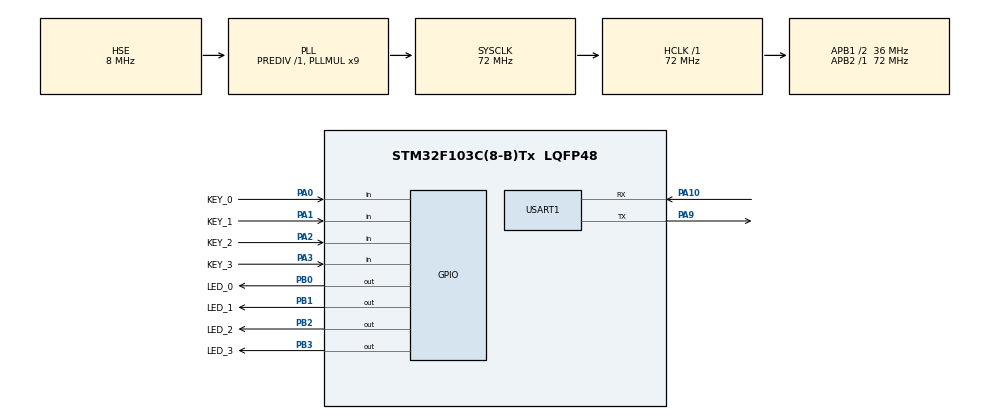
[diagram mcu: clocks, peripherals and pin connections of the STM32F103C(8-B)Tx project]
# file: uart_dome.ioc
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Mcu.Family=STM32F1
Mcu.Name=STM32F103C(8-B)Tx
Mcu.Package=LQFP48
NVIC.PriorityGroup=NVIC_PRIORITYGROUP_4
NVIC.TIM2_IRQn=true\:0\:0\:false\:false\:true\:true\:true
NVIC.USART1_IRQn=true\:0\:0\:false\:false\:true\:true\:true
PA0-WKUP.GPIO_Label=KEY_0
PA0-WKUP.GPIO_PuPd=GPIO_PULLUP
PA0-WKUP.Signal=GPIO_Input
PA1.GPIO_Label=KEY_1
PA1.GPIO_PuPd=GPIO_PULLUP
PA1.Signal=GPIO_Input
PA10.Mode=Asynchronous
PA10.Signal=USART1_RX
PA13.Mode=Serial_Wire
PA13.Signal=SYS_JTMS-SWDIO
PA14.Mode=Serial_Wire
PA14.Signal=SYS_JTCK-SWCLK
PA2.GPIO_Label=KEY_2
PA2.GPIO_PuPd=GPIO_PULLUP
PA2.Signal=GPIO_Input
PA3.GPIO_Label=KEY_3
PA3.GPIO_PuPd=GPIO_PULLUP
PA3.Signal=GPIO_Input
PA9.Mode=Asynchronous
PA9.Signal=USART1_TX
PB0.GPIO_Label=LED_0
PB0.GPIO_PuPd=GPIO_PULLUP
PB0.Signal=GPIO_Output
PB1.GPIO_Label=LED_1
PB1.GPIO_PuPd=GPIO_PULLUP
PB1.Signal=GPIO_Output
PB2.GPIO_Label=LED_2
PB2.GPIO_PuPd=GPIO_PULLUP
PB2.Signal=GPIO_Output
PB3.GPIO_Label=LED_3
PB3.GPIO_PuPd=GPIO_PULLUP
PB3.Signal=GPIO_Output
PC14-OSC32_IN.Mode=LSE-External-Oscillator
PC14-OSC32_IN.Signal=RCC_OSC32_IN
PC15-OSC32_OUT.Mode=LSE-External-Oscillator
PC15-OSC32_OUT.Signal=RCC_OSC32_OUT
PD0-OSC_IN.Mode=HSE-External-Oscillator
PD0-OSC_IN.Signal=RCC_OSC_IN
PD1-OSC_OUT.Mode=HSE-External-Oscillator
PD1-OSC_OUT.Signal=RCC_OSC_OUT
ProjectManager.HeapSize=0x200
ProjectManager.StackSize=0x400
ProjectManager.TargetToolchain=STM32CubeIDE
RCC.AHBFreq_Value=72000000
RCC.APB1CLKDivider=RCC_HCLK_DIV2
RCC.APB1Freq_Value=36000000
RCC.APB1TimFreq_Value=72000000
RCC.APB2Freq_Value=72000000
RCC.APB2TimFreq_Value=72000000
RCC.HCLKFreq_Value=72000000
RCC.PLLMUL=RCC_PLL_MUL9
RCC.PLLSourceVirtual=RCC_PLLSOURCE_HSE
RCC.SYSCLKFreq_VALUE=72000000
RCC.SYSCLKSource=RCC_SYSCLKSOURCE_PLLCLK
RCC.USBFreq_Value=72000000
TIM2.AutoReloadPreload=TIM_AUTORELOAD_PRELOAD_DISABLE
TIM2.Period=5
TIM2.Prescaler=36000-1
USART1.VirtualMode=VM_ASYNC
VP_TIM2_VS_ClockSourceINT.Mode=Internal
board=custom

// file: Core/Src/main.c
/* USER CODE BEGIN Header */
/**
  ******************************************************************************
  * @file           : main.c
  * @brief          : Main program body
  ******************************************************************************
  * @attention
  *
  * <h2><center>&copy; Copyright (c) 2020 STMicroelectronics.
  * All rights reserved.</center></h2>
  *
  * This software component is licensed by ST under BSD 3-Clause license,
  * the "License"; You may not use this file except in compliance with the
  * License. You may obtain a copy of the License at:
  *                        opensource.org/licenses/BSD-3-Clause
  *
  ******************************************************************************
  */
/* USER CODE END Header */

#include "main.h"

/* USER CODE BEGIN Includes */

uint8_t buffer[2];  //串口接收buffer
float a=5.5;

/* USER CODE END Includes */

TIM_HandleTypeDef htim2;

UART_HandleTypeDef huart1;

void SystemClock_Config(void);
static void MX_GPIO_Init(void);
static void MX_TIM2_Init(void);
static void MX_USART1_UART_Init(void);

int main(void)
{
  /* USER CODE BEGIN 1 */

	//uart_frame_id

  /* USER CODE END 1 */

  /* MCU Configuration--------------------------------------------------------*/

  /* Reset of all peripherals, Initializes the Flash interface and the Systick. */
  HAL_Init();

  /* Configure the system clock */
  SystemClock_Config();

  /* Initialize all configured peripherals */
  MX_GPIO_Init();
  MX_TIM2_Init();
  MX_USART1_UART_Init();
  /* USER CODE BEGIN 2 */

  HAL_TIM_Base_Start_IT(&htim2);  //Start timer interrupt启动定时器中�
  HAL_UART_Receive_IT(&huart1,(uint8_t*)&buffer,1);  //Start uart interrupt

  HAL_UART_Transmit(&huart1,(uint8_t*)"uart_test_ok",16,10);
  /* USER CODE END 2 */

  /* Infinite loop */
  /* USER CODE BEGIN WHILE */
  while (1)
  {

//	  sprintf((uint8_t*)buffer, (uint8_t*)"An approximation ofPi is %f",(uint8_t)a);
//	  HAL_UART_Transmit(&huart1,buffer,sizeof(buffer),10);
//      HAL_Delay(100);

	 Key_Processing();

    /* USER CODE END WHILE */

  }
}

void SystemClock_Config(void)
{
  RCC_OscInitTypeDef RCC_OscInitStruct = {0};
  RCC_ClkInitTypeDef RCC_ClkInitStruct = {0};

  /** Initializes the CPU, AHB and APB busses clocks
  */
  RCC_OscInitStruct.OscillatorType = RCC_OSCILLATORTYPE_HSE;
  RCC_OscInitStruct.HSEState = RCC_HSE_ON;
  RCC_OscInitStruct.HSEPredivValue = RCC_HSE_PREDIV_DIV1;
  RCC_OscInitStruct.HSIState = RCC_HSI_ON;
  RCC_OscInitStruct.PLL.PLLState = RCC_PLL_ON;
  RCC_OscInitStruct.PLL.PLLSource = RCC_PLLSOURCE_HSE;
  RCC_OscInitStruct.PLL.PLLMUL = RCC_PLL_MUL9;
  if (HAL_RCC_OscConfig(&RCC_OscInitStruct) != HAL_OK)
  {
    Error_Handler();
  }
  /** Initializes the CPU, AHB and APB busses clocks
  */
  RCC_ClkInitStruct.ClockType = RCC_CLOCKTYPE_HCLK|RCC_CLOCKTYPE_SYSCLK
                              |RCC_CLOCKTYPE_PCLK1|RCC_CLOCKTYPE_PCLK2;
  RCC_ClkInitStruct.SYSCLKSource = RCC_SYSCLKSOURCE_PLLCLK;
  RCC_ClkInitStruct.AHBCLKDivider = RCC_SYSCLK_DIV1;
  RCC_ClkInitStruct.APB1CLKDivider = RCC_HCLK_DIV2;
  RCC_ClkInitStruct.APB2CLKDivider = RCC_HCLK_DIV1;

  if (HAL_RCC_ClockConfig(&RCC_ClkInitStruct, FLASH_LATENCY_2) != HAL_OK)
  {
    Error_Handler();
  }
}

static void MX_TIM2_Init(void)
{

  TIM_ClockConfigTypeDef sClockSourceConfig = {0};
  TIM_MasterConfigTypeDef sMasterConfig = {0};

  htim2.Instance = TIM2;
  htim2.Init.Prescaler = 36000-1;
  htim2.Init.CounterMode = TIM_COUNTERMODE_UP;
  htim2.Init.Period = 5;
  htim2.Init.ClockDivision = TIM_CLOCKDIVISION_DIV1;
  htim2.Init.AutoReloadPreload = TIM_AUTORELOAD_PRELOAD_DISABLE;
  if (HAL_TIM_Base_Init(&htim2) != HAL_OK)
  {
    Error_Handler();
  }
  sClockSourceConfig.ClockSource = TIM_CLOCKSOURCE_INTERNAL;
  if (HAL_TIM_ConfigClockSource(&htim2, &sClockSourceConfig) != HAL_OK)
  {
    Error_Handler();
  }
  sMasterConfig.MasterOutputTrigger = TIM_TRGO_RESET;
  sMasterConfig.MasterSlaveMode = TIM_MASTERSLAVEMODE_DISABLE;
  if (HAL_TIMEx_MasterConfigSynchronization(&htim2, &sMasterConfig) != HAL_OK)
  {
    Error_Handler();
  }

}

static void MX_USART1_UART_Init(void)
{

  huart1.Instance = USART1;
  huart1.Init.BaudRate = 115200;
  huart1.Init.WordLength = UART_WORDLENGTH_8B;
  huart1.Init.StopBits = UART_STOPBITS_1;
  huart1.Init.Parity = UART_PARITY_NONE;
  huart1.Init.Mode = UART_MODE_TX_RX;
  huart1.Init.HwFlowCtl = UART_HWCONTROL_NONE;
  huart1.Init.OverSampling = UART_OVERSAMPLING_16;
  if (HAL_UART_Init(&huart1) != HAL_OK)
  {
    Error_Handler();
  }

}

static void MX_GPIO_Init(void)
{
  GPIO_InitTypeDef GPIO_InitStruct = {0};

  /* GPIO Ports Clock Enable */
  __HAL_RCC_GPIOC_CLK_ENABLE();
  __HAL_RCC_GPIOD_CLK_ENABLE();
  __HAL_RCC_GPIOA_CLK_ENABLE();
  __HAL_RCC_GPIOB_CLK_ENABLE();

  /*Configure GPIO pin Output Level */
  HAL_GPIO_WritePin(GPIOB, LED_0_Pin|LED_1_Pin|LED_2_Pin|LED_3_Pin, GPIO_PIN_RESET);

  /*Configure GPIO pins : KEY_0_Pin KEY_1_Pin KEY_2_Pin KEY_3_Pin */
  GPIO_InitStruct.Pin = KEY_0_Pin|KEY_1_Pin|KEY_2_Pin|KEY_3_Pin;
  GPIO_InitStruct.Mode = GPIO_MODE_INPUT;
  GPIO_InitStruct.Pull = GPIO_PULLUP;
  HAL_GPIO_Init(GPIOA, &GPIO_InitStruct);

  /*Configure GPIO pins : LED_0_Pin LED_1_Pin LED_2_Pin LED_3_Pin */
  GPIO_InitStruct.Pin = LED_0_Pin|LED_1_Pin|LED_2_Pin|LED_3_Pin;
  GPIO_InitStruct.Mode = GPIO_MODE_OUTPUT_PP;
  GPIO_InitStruct.Pull = GPIO_PULLUP;
  GPIO_InitStruct.Speed = GPIO_SPEED_FREQ_LOW;
  HAL_GPIO_Init(GPIOB, &GPIO_InitStruct);

}

/* USER CODE BEGIN 4 */

void HAL_TIM_PeriodElapsedCallback(TIM_HandleTypeDef *htim){
//static uint8_t temp;
	if(htim->Instance==TIM2){
		Uart_Time_Even();
		Key_Timer_Interrupt();
	}
}

/* USER CODE END 4 */

void Error_Handler(void)
{
}

/************************ (C) COPYRIGHT STMicroelectronics *****END OF FILE****/
